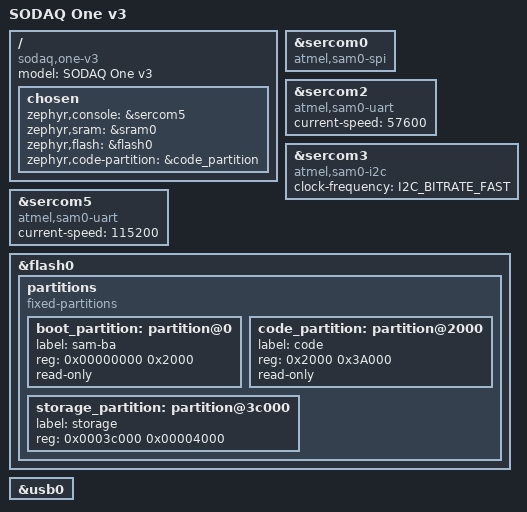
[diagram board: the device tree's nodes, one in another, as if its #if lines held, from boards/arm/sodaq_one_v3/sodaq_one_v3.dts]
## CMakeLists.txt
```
# Create following http://docs.zephyrproject.org/application/application.html

# Board used - Use custom board
#set(BOARD adafruit_feather_m0_basic_proto)
#set(BOARD_ROOT ${CMAKE_SOURCE_DIR})
set(BOARD sodaq_one_v3)

# Include zephyr
include($ENV{ZEPHYR_BASE}/cmake/app/boilerplate.cmake NO_POLICY_SCOPE)
project(NONE)

# Application source files
target_sources(app PRIVATE src/main.c)
target_sources(app PRIVATE src/RN2483_lora.c)
target_sources(app PRIVATE src/LSM303AGR.c)
target_sources(app PRIVATE src/UBloxEVA8M.c)
```

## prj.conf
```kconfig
CONFIG_SYS_LOG=y
CONFIG_SYS_LOG_DEFAULT_LEVEL=3
CONFIG_SYS_LOG_I2C_LEVEL=3
```

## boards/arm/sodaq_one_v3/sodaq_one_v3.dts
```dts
/*
 * Copyright (c) 2018 Henrik Brix Andersen <henrik@brixandersen.dk>
 *
 * SPDX-License-Identifier: Apache-2.0
 */

/dts-v1/;
#include <atmel/samd21.dtsi>

/ {
	model = "SODAQ One v3";
	compatible = "sodaq,one-v3", "atmel,samd21g18a",
			"atmel,samd21";

	chosen {
		zephyr,console = &sercom5;
		zephyr,sram = &sram0;
		zephyr,flash = &flash0;
		zephyr,code-partition = &code_partition;
	};
};

&sercom0 {
	status = "ok";
	compatible = "atmel,sam0-spi";
	#address-cells = <1>;
	#size-cells = <0>;
};

&sercom2 {
	status = "ok";
	compatible = "atmel,sam0-uart";
	current-speed = <57600>;
};

&sercom3 {
	status = "ok";
	compatible = "atmel,sam0-i2c";
	clock-frequency = <I2C_BITRATE_FAST>;
	#address-cells = <1>;
	#size-cells = <0>;
};

&sercom5 {
	status = "ok";
	compatible = "atmel,sam0-uart";
	current-speed = <115200>;
};

&flash0 {
	partitions {
		compatible = "fixed-partitions";
		#address-cells = <1>;
		#size-cells = <1>;

		boot_partition: partition@0 {
			label = "sam-ba";
			reg = <0x00000000 0x2000>;
			read-only;
		};

		code_partition: partition@2000 {
			label = "code";
			reg = <0x2000 0x3A000>;
			read-only;
		};

		/*
		 * The final 16 KiB is reserved for the application
		 * and is used by NFFS if enabled.
		 */

#if defined(CONFIG_FS_FLASH_STORAGE_PARTITION)
		storage_partition: partition@3c000 {
			label = "storage";
			reg = <0x0003c000 0x00004000>;
		};
#endif
	};
};

&usb0 {
	status = "ok";
};
```

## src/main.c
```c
/*
 * Copyright (c) 2012-2014 Wind River Systems, Inc.
 *
 * SPDX-License-Identifier: Apache-2.0
 */

#include <zephyr.h>
#include <misc/printk.h>
#include <gpio.h>
#include <board.h>
#include <device.h>
#include <uart.h>
#include <stdio.h>
#include <string.h>

#include "debug.h"
#include "RN2483_lora.h"
#include "LSM303AGR.h"
#include "UBloxEVA8M.h"

#define LORA_SPREADING_FACTOR "sf7"
#define LORA_POWER 1

#ifdef DEBUG_UBLOXEVA8M
#define DEBUG DEBUG_UBLOXEVA8M
static void print_nav_pvt_msg(char *txt, ubloxeva8m_nav_pvt_t* msg);
#endif

void gps_msg_handler(ubloxeva8m_ubx_msg* msg) {
	ubloxeva8m_nav_pvt_t pvt_msg;

	if (msg->class_id == UBLOXEVA8M_CLASS_NAV && msg->message_id == UBLOXEVA8M_MSG_NAV_PVT) {
		memcpy(&pvt_msg, msg->payload, msg->length);
		print_nav_pvt_msg("UBX-NAV-PVT: ", &pvt_msg);
	}

}

void main(void)
{
	static struct device *led0, *led1, *led2;
	int ret;
	u8_t data_buf[20] = { 0x00, 0x01, 0x02, 0x03, 0x04 };
	lsm303agr_status_t accel_status;
	int16_t accel[3];

	printk("Hello World! %s\n", CONFIG_ARCH);

	led0 = device_get_binding(LED0_GPIO_PORT);
	gpio_pin_configure(led0, LED0_GPIO_PIN, GPIO_DIR_OUT);
	led1 = device_get_binding(LED1_GPIO_PORT);
	gpio_pin_configure(led1, LED1_GPIO_PIN, GPIO_DIR_OUT);
	led2 = device_get_binding(LED2_GPIO_PORT);
	gpio_pin_configure(led2, LED2_GPIO_PIN, GPIO_DIR_OUT);

	gpio_pin_write(led0, LED0_GPIO_PIN, 1);
	gpio_pin_write(led1, LED1_GPIO_PIN, 1);
	gpio_pin_write(led2, LED2_GPIO_PIN, 1);

#if 1
	if (rn2483_lora_init(CONFIG_UART_SAM0_SERCOM2_LABEL)) {
		printk("Couldn't initialize LoRa\n");
	} else {
		printk("LoRa initialized\n");
	}

	/* Setup the RN2483 for radio */
	/* Pause mac layer */
	if (rn2483_lora_pause_mac()) {
		printk("Couldn't pause mac\n");
	}

	/* Set spreading factor */
	if (rn2483_lora_radio_set_sf(LORA_SPREADING_FACTOR)) {
		printk("Couldn't set spreading factor\n");
	}

	/* Set power output */
	if (rn2483_lora_radio_set_pwr(LORA_POWER)) {
		printk("Couldn't set radio power\n");
	}

	if (rn2483_lora_radio_tx(data_buf, 5)) {
		printk("Couldn't send data\n");
	}

	data_buf[0] = 0x05;
	data_buf[1] = 0x06;
	data_buf[2] = 0x07;
	data_buf[3] = 0x08;
	data_buf[4] = 0x09;
	if (rn2483_lora_radio_tx(data_buf, 5)) {
		printk("Couldn't send data\n");
	}
#endif

	ubloxeva8m_init(CONFIG_I2C_SAM0_SERCOM3_LABEL);
	/* Configure message handler */
	ubloxeva8m_set_callback(gps_msg_handler);
	if (ubloxeva8m_start()) {
		printk("Couldn't start UBLOXEVA8M\n");
	}
	/* Change dynamic model */
	if (ubloxeva8m_set_dynamic_model(UBLOXEVA8M_DYNMODEL_AUTOMOTIVE)) {
		printk("Couldn't set dynamic model\n");
	}

	lsm303agr_init(CONFIG_I2C_SAM0_SERCOM3_LABEL);
	printk("LSM303AGR Accelerometer Device ID: %X\n", lsm303agr_accel_get_device_id());
	printk("LSM303AGR Magnetometer Device ID: %X\n", lsm303agr_mag_get_device_id());
	if (lsm303agr_accel_enable(LSM303AGR_NORMAL_MODE, LSM303AGR_HIGH_RES_100HZ, false, (LSM303AGR_Z_AXIS | LSM303AGR_Y_AXIS | LSM303AGR_X_AXIS))) {
		printk("Couldn't enable accelerometer\n");
	}
	if (lsm303agr_accel_set_scale(LSM303AGR_8G)) {
		printk("Couldn't set accelerometer scale\n");
	}
	if (lsm303agr_get_status(&accel_status)) {
		printk("Couldn't read status");
	}
	printk("Acelerometer status: Overrun (all=%d x=%d y=%d z=%d) Data Available (all=%d x=%d y=%d =z%d)\n", accel_status.z_y_x_overrun, accel_status.x_overrun, accel_status.y_overrun, accel_status.z_overrun, accel_status.z_y_x_available, accel_status.x_available, accel_status.y_available, accel_status.z_available);
	if (lsm303agr_get_x_acceleration(&accel[0])) {
		printk("Couldn't read acceleration");
	}
	if (lsm303agr_get_y_acceleration(&accel[1])) {
		printk("Couldn't read acceleration");
	}
	if (lsm303agr_get_z_acceleration(&accel[2])) {
		printk("Couldn't read acceleration");
	}
	printk("Acceleration x=%d y=%d z=%d\n", accel[0], accel[1], accel[2]);

	while(1) {
		//printk("Hello World! %s\n", CONFIG_ARCH);
		gpio_pin_write(led2, LED2_GPIO_PIN, 1);
		gpio_pin_write(led0, LED0_GPIO_PIN, 0);
		k_sleep(200);
		gpio_pin_write(led0, LED0_GPIO_PIN, 1);
		gpio_pin_write(led1, LED1_GPIO_PIN, 0);
		k_sleep(200);
		gpio_pin_write(led1, LED1_GPIO_PIN, 1);
		gpio_pin_write(led2, LED2_GPIO_PIN, 0);
		k_sleep(200);
	}
}

#ifdef DEBUG
static void print_nav_pvt_msg(char *txt, ubloxeva8m_nav_pvt_t* msg) {
	DBG_PRINTK("UBX-NAV-PVT: %d.%d.%d %02d:%02d:%02d validity=%d fixType=%d numSV=%d lat=%d lon=%d \n", msg->day, msg->month, msg->year, msg->hour, msg->minute, msg->seconds, msg->valid, msg->fixType, msg->numSV, msg->lat, msg->lon);
}
#endif
```

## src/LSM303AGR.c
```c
/** 
 * @file LSM303AGR.c
 * @brief Module description
 *
 * Detailed module description
 *
 * @author Léonard Bise
 * @date   Jul 2, 2018
 */

#include "LSM303AGR.h"

#include "debug.h"

#define DEBUG DEBUG_LSM303AGR

#include <zephyr.h>
#include <i2c.h>

/**
 * i2c address for the LSM303AGR Accelerometer
 */
#define LSM303AGR_ACCEL_ADDR 0x19

/**
 * Device ID for the LSM303AGR Accelerometer
 */
#define LSM303AGR_ACCEL_DEVICE_ID 0x33
/**
 * i2c address for the LSM303AGR Magnetometer
 */
#define LSM303AGR_MAGN_ADDR 0x1E

/**
 * Device ID for the LSM303AGR Magnetometer
 */
#define LSM303AGR_MAGN_DEVICE_ID 0x40

/**
 * Register addresses
 */
/* Accelerometer */
#define LSM303AGR_ACCEL_WHO_AM_I_REG_ADDR 0x0F
#define LSM303AGR_ACCEL_CFG1_ADDR 0x20
#define LSM303AGR_ACCEL_CFG_ODR_POS 4
#define LSM303AGR_ACCEL_CFG_LPEN_POS 3
#define LSM303AGR_ACCEL_CFG_ZEN_POS 2
#define LSM303AGR_ACCEL_CFG_YEN_POS 1
#define LSM303AGR_ACCEL_CFG_XEN_POS 0

#define LSM303AGR_ACCEL_CFG3_ADDR 0x22

#define LSM303AGR_ACCEL_CFG4_ADDR 0x23
#define LSM303AGR_ACCEL_CFG4_HR_POS 3
#define LSM303AGR_ACCEL_CFG4_FS_POS 4

#define LSM303AGR_ACCEL_INT1_CFG_ADDR 0x30
#define LSM303AGR_ACCEL_INT1_CFG_AOI_POS 7
#define LSM303AGR_ACCEL_INT1_CFG_6D_POS 6
#define LSM303AGR_ACCEL_INT1_CFG_Z_HIGH_POS 5
#define LSM303AGR_ACCEL_INT1_CFG_Z_LOW_POS 4
#define LSM303AGR_ACCEL_INT1_CFG_Y_HIGH_POS 3
#define LSM303AGR_ACCEL_INT1_CFG_Y_LOW_POS 2
#define LSM303AGR_ACCEL_INT1_CFG_X_HIGH_POS 1
#define LSM303AGR_ACCEL_INT1_CFG_X_LOW_POS 0

#define LSM303AGR_ACCEL_STATUS_ADDR 0x27
#define LSM303AGR_ACCEL_STATUS_ZYXOR_POS 7
#define LSM303AGR_ACCEL_STATUS_ZOR_POS 6
#define LSM303AGR_ACCEL_STATUS_YOR_POS 5
#define LSM303AGR_ACCEL_STATUS_XOR_POS 4
#define LSM303AGR_ACCEL_STATUS_ZYXDA_POS 3
#define LSM303AGR_ACCEL_STATUS_ZDA_POS 2
#define LSM303AGR_ACCEL_STATUS_YDA_POS 1
#define LSM303AGR_ACCEL_STATUS_XDA_POS 0

#define LSM303AGR_ACCEL_OUT_X_L_ADDR 0x28
#define LSM303AGR_ACCEL_OUT_X_H_ADDR 0x29

#define LSM303AGR_ACCEL_OUT_Y_L_ADDR 0x2A
#define LSM303AGR_ACCEL_OUT_Y_H_ADDR 0x2B

#define LSM303AGR_ACCEL_OUT_Z_L_ADDR 0x2C
#define LSM303AGR_ACCEL_OUT_Z_H_ADDR 0x2D


/* Magnetometer */
#define LSM303AGR_MAG_WHO_AM_I_REG_ADDR 0x4F


typedef struct {
	struct device *i2c_dev;

} lsm303agr_priv_t;

static lsm303agr_priv_t lsm303agr_priv;

int lsm303agr_init(const char *device_name) {
	lsm303agr_priv.i2c_dev = device_get_binding(device_name);
	u32_t i2c_cfg = I2C_SPEED_SET(I2C_SPEED_FAST) | I2C_MODE_MASTER;

	if (!lsm303agr_priv.i2c_dev) {
		DBG_PRINTK("%s: Binding to i2c failed\n", __func__);
		return LSM303AGR_BINDING_FAILED;
	}

	if (i2c_configure(lsm303agr_priv.i2c_dev, i2c_cfg)) {
		DBG_PRINTK("%s: i2c configuration failed\n", __func__);
		return LSM303AGR_CONFIGURATION_FAILED;
	}

	/* Check device IDs */
	if (lsm303agr_accel_get_device_id() != LSM303AGR_ACCEL_DEVICE_ID ||
			lsm303agr_mag_get_device_id() != LSM303AGR_MAGN_DEVICE_ID) {
		DBG_PRINTK("%s: Unknown device IDs Accelereometer: 0x%X Magnetometer: 0x%X\n", __func__, lsm303agr_accel_get_device_id(), lsm303agr_mag_get_device_id());
		return LSM303AGR_UNKNOWN_DEVICE;
	}

	return LSM303AGR_SUCCESS;
}

uint8_t lsm303agr_accel_get_device_id() {
	uint8_t dev_id = 0xFF;
	if (lsm303agr_priv.i2c_dev) {
		if (i2c_reg_read_byte(lsm303agr_priv.i2c_dev, LSM303AGR_ACCEL_ADDR, LSM303AGR_ACCEL_WHO_AM_I_REG_ADDR, &dev_id)) {
			DBG_PRINTK("%s: Register access failed\n", __func__);
			return 0xFF;
		}
	}
	return dev_id;
}

int lsm303agr_accel_enable(lsm303agr_modes_t mode, lsm303agr_datarate_modes_t data_rate, bool low_pwr_mode, uint8_t axis_enable) {
	uint8_t reg = 0;
	if (lsm303agr_priv.i2c_dev) {
		reg = (data_rate << LSM303AGR_ACCEL_CFG_ODR_POS) | ((low_pwr_mode ? 1 : 0) << LSM303AGR_ACCEL_CFG_LPEN_POS) | axis_enable;
		if (i2c_reg_write_byte(lsm303agr_priv.i2c_dev, LSM303AGR_ACCEL_ADDR, LSM303AGR_ACCEL_CFG1_ADDR, reg)) {
			DBG_PRINTK("%s: Register access failed\n", __func__);
			return LSM303AGR_REG_ACCESS_FAILED;
		}
		/* Set operating mode */
		if (mode & 0x1) {
			reg = 1 << LSM303AGR_ACCEL_CFG4_HR_POS;
		} else {
			reg = 0;
		}
		if (i2c_reg_update_byte(lsm303agr_priv.i2c_dev, LSM303AGR_ACCEL_ADDR, LSM303AGR_ACCEL_CFG4_ADDR, (1 << LSM303AGR_ACCEL_CFG4_HR_POS), reg)) {
			DBG_PRINTK("%s: Register access failed\n", __func__);
			return LSM303AGR_REG_ACCESS_FAILED;
		}
	} else {
		DBG_PRINTK("%s: I2C bus not initialized\n", __func__);
		return LSM303AGR_NOT_INITIALIZED;
	}
	return LSM303AGR_SUCCESS;
}

int lsm303agr_accel_set_scale(lsm303agr_scales_t scale) {
	uint8_t reg = 0;
	if (lsm303agr_priv.i2c_dev) {
		reg = scale << LSM303AGR_ACCEL_CFG4_FS_POS;
		if (i2c_reg_update_byte(lsm303agr_priv.i2c_dev, LSM303AGR_ACCEL_ADDR, LSM303AGR_ACCEL_CFG4_ADDR, (1 << LSM303AGR_ACCEL_CFG4_FS_POS), reg)) {
			DBG_PRINTK("%s: Register access failed\n", __func__);
			return LSM303AGR_REG_ACCESS_FAILED;
		}
	} else {
		DBG_PRINTK("%s: I2C bus not initialized\n", __func__);
		return LSM303AGR_NOT_INITIALIZED;
	}
	return LSM303AGR_SUCCESS;
}

int lsm303agr_enable_interrupt(lsm303agr_interrupts_t interrupt) {
	uint8_t reg = 0;

	if (lsm303agr_priv.i2c_dev) {
		reg = interrupt;
		if (i2c_reg_write_byte(lsm303agr_priv.i2c_dev, LSM303AGR_ACCEL_ADDR, LSM303AGR_ACCEL_CFG3_ADDR, reg)) {
			DBG_PRINTK("%s: Register access failed\n", __func__);
			return LSM303AGR_REG_ACCESS_FAILED;
		}
	} else {
		DBG_PRINTK("%s: I2C bus not initialized\n", __func__);
		return LSM303AGR_NOT_INITIALIZED;
	}
	return LSM303AGR_SUCCESS;
}

int lsm303agr_configure_interrupt1(lsm303agr_interrupt_modes_t interrupt_mode, uint8_t interrupt_directions) {
	uint8_t reg = 0;

	if (lsm303agr_priv.i2c_dev) {
		reg = (interrupt_mode << LSM303AGR_ACCEL_INT1_CFG_6D_POS) | (interrupt_directions & 0x3F);
		if (i2c_reg_write_byte(lsm303agr_priv.i2c_dev, LSM303AGR_ACCEL_ADDR, LSM303AGR_ACCEL_INT1_CFG_ADDR, reg)) {
			DBG_PRINTK("%s: Register access failed\n", __func__);
			return LSM303AGR_REG_ACCESS_FAILED;
		}
	} else {
		DBG_PRINTK("%s: I2C bus not initialized\n", __func__);
		return LSM303AGR_NOT_INITIALIZED;
	}
	return LSM303AGR_SUCCESS;
}

int lsm303agr_get_z_acceleration(int16_t* acceleration) {
	uint8_t reg = 0;

	if (lsm303agr_priv.i2c_dev) {
		if (i2c_reg_read_byte(lsm303agr_priv.i2c_dev, LSM303AGR_ACCEL_ADDR, LSM303AGR_ACCEL_OUT_Z_H_ADDR, &reg)) {
			DBG_PRINTK("%s: Register access failed\n", __func__);
			return LSM303AGR_REG_ACCESS_FAILED;
		}
		*acceleration = reg << 8;
		if (i2c_reg_read_byte(lsm303agr_priv.i2c_dev, LSM303AGR_ACCEL_ADDR, LSM303AGR_ACCEL_OUT_Z_L_ADDR, &reg)) {
			DBG_PRINTK("%s: Register access failed\n", __func__);
			return LSM303AGR_REG_ACCESS_FAILED;
		}
		*acceleration = reg;
	} else {
		DBG_PRINTK("%s: I2C bus not initialized\n", __func__);
		return LSM303AGR_NOT_INITIALIZED;
	}
	return LSM303AGR_SUCCESS;
}

int lsm303agr_get_y_acceleration(int16_t* acceleration) {
	uint8_t reg = 0;

	if (lsm303agr_priv.i2c_dev) {
		if (i2c_reg_read_byte(lsm303agr_priv.i2c_dev, LSM303AGR_ACCEL_ADDR, LSM303AGR_ACCEL_OUT_Y_H_ADDR, &reg)) {
			DBG_PRINTK("%s: Register access failed\n", __func__);
			return LSM303AGR_REG_ACCESS_FAILED;
		}
		*acceleration = reg << 8;
		if (i2c_reg_read_byte(lsm303agr_priv.i2c_dev, LSM303AGR_ACCEL_ADDR, LSM303AGR_ACCEL_OUT_Y_L_ADDR, &reg)) {
			DBG_PRINTK("%s: Register access failed\n", __func__);
			return LSM303AGR_REG_ACCESS_FAILED;
		}
		*acceleration = reg;
	} else {
		DBG_PRINTK("%s: I2C bus not initialized\n", __func__);
		return LSM303AGR_NOT_INITIALIZED;
	}
	return LSM303AGR_SUCCESS;
}

int lsm303agr_get_x_acceleration(int16_t* acceleration) {
	uint8_t reg = 0;

	if (lsm303agr_priv.i2c_dev) {
		if (i2c_reg_read_byte(lsm303agr_priv.i2c_dev, LSM303AGR_ACCEL_ADDR, LSM303AGR_ACCEL_OUT_X_H_ADDR, &reg)) {
			DBG_PRINTK("%s: Register access failed\n", __func__);
			return LSM303AGR_REG_ACCESS_FAILED;
		}
		*acceleration = reg << 8;
		if (i2c_reg_read_byte(lsm303agr_priv.i2c_dev, LSM303AGR_ACCEL_ADDR, LSM303AGR_ACCEL_OUT_X_L_ADDR, &reg)) {
			DBG_PRINTK("%s: Register access failed\n", __func__);
			return LSM303AGR_REG_ACCESS_FAILED;
		}
		*acceleration = reg;
	} else {
		DBG_PRINTK("%s: I2C bus not initialized\n", __func__);
		return LSM303AGR_NOT_INITIALIZED;
	}
	return LSM303AGR_SUCCESS;
}

int lsm303agr_get_status(lsm303agr_status_t* status) {
	uint8_t reg = 0;

	if (lsm303agr_priv.i2c_dev) {
		if (i2c_reg_read_byte(lsm303agr_priv.i2c_dev, LSM303AGR_ACCEL_ADDR, LSM303AGR_ACCEL_STATUS_ADDR, &reg)) {
			DBG_PRINTK("%s: Register access failed\n", __func__);
			return LSM303AGR_REG_ACCESS_FAILED;
		}
		status->z_y_x_overrun = (reg & (1 << LSM303AGR_ACCEL_STATUS_ZYXOR_POS)) ? true : false;
		status->z_overrun = (reg & (1 << LSM303AGR_ACCEL_STATUS_ZOR_POS)) ? true : false;
		status->y_overrun = (reg & (1 << LSM303AGR_ACCEL_STATUS_YOR_POS)) ? true : false;
		status->x_overrun = (reg & (1 << LSM303AGR_ACCEL_STATUS_XOR_POS)) ? true : false;
		status->z_y_x_available = (reg & (1 << LSM303AGR_ACCEL_STATUS_ZYXDA_POS)) ? true : false;
		status->z_available = (reg & (1 << LSM303AGR_ACCEL_STATUS_ZDA_POS)) ? true : false;
		status->y_available = (reg & (1 << LSM303AGR_ACCEL_STATUS_YDA_POS)) ? true : false;
		status->x_available = (reg & (1 << LSM303AGR_ACCEL_STATUS_XDA_POS)) ? true : false;
	} else {
		DBG_PRINTK("%s: I2C bus not initialized\n", __func__);
		return LSM303AGR_NOT_INITIALIZED;
	}
	return LSM303AGR_SUCCESS;
}

uint8_t lsm303agr_mag_get_device_id() {
	uint8_t dev_id = 0xFF;
	if (lsm303agr_priv.i2c_dev) {
		if (i2c_reg_read_byte(lsm303agr_priv.i2c_dev, LSM303AGR_MAGN_ADDR, LSM303AGR_MAG_WHO_AM_I_REG_ADDR, &dev_id)) {
			DBG_PRINTK("%s: Register access failed\n", __func__);
			return 0xFF;
		}
	}
	return dev_id;
}
```

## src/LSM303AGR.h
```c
/** 
 * @file LSM303AGR.h
 * @brief Module description
 *
 * Detailed module description
 *
 * @author Léonard Bise
 * @date   Jul 2, 2018
 */
#ifndef SRC_LSM303AGR_H_
#define SRC_LSM303AGR_H_

#include <stdint.h>
#include <stdbool.h>

/**
 * Return types of the LSM303AGR functions
 */
#define LSM303AGR_SUCCESS 0
#define LSM303AGR_BINDING_FAILED -1
#define LSM303AGR_CONFIGURATION_FAILED -2
#define LSM303AGR_NOT_INITIALIZED -3
#define LSM303AGR_REG_ACCESS_FAILED -4
#define LSM303AGR_UNKNOWN_DEVICE -5

/**
 * Module status
 */
typedef struct {
	bool z_y_x_overrun;
	bool z_overrun;
	bool y_overrun;
	bool x_overrun;
	bool z_y_x_available;
	bool z_available;
	bool y_available;
	bool x_available;
} lsm303agr_status_t;

/**
 * Device mode
 */
typedef enum {
	LSM303AGR_NORMAL_MODE,
	LSM303AGR_HIGH_RES_MODE,
	LSM303AGR_LOW_PWR_MODE
} lsm303agr_modes_t;

/**
 * Data rate and operating modes of the accelerometer
 */
typedef enum {
	LSM303AGR_PWR_DOWN_MODE,
	LSM303AGR_HIGH_RES_1HZ,
	LSM303AGR_HIGH_RES_10HZ,
	LSM303AGR_HIGH_RES_25HZ,
	LSM303AGR_HIGH_RES_50HZ,
	LSM303AGR_HIGH_RES_100HZ,
	LSM303AGR_HIGH_RES_200HZ,
	LSM303AGR_HIGH_RES_400HZ,
	LSM303AGR_LOW_PWR_MODE_1620HZ,
	LSM303AGR_HIGH_RES_5376HZ
} lsm303agr_datarate_modes_t;

/* Accelerometer axes */
#define LSM303AGR_Z_AXIS (1 << 2)
#define LSM303AGR_Y_AXIS (1 << 1)
#define LSM303AGR_X_AXIS (1 << 0)

typedef enum {
	LSM303AGR_2G,
	LSM303AGR_4G,
	LSM303AGR_8G,
	LSM303AGR_16G
} lsm303agr_scales_t;

typedef enum {
	LSM303AGR_INT_OR_COMBINATION,
	LSM303AGR_INT_MOVEMENT_RECOG,
	LSM303AGR_INT_AND_COMBINATION,
	LSM303AGR_INT_POSITION_RECOG
} lsm303agr_interrupt_modes_t;

typedef enum {
	LSM303AGR_INT_DIR_Z_HIGH = 32,
	LSM303AGR_INT_DIR_Z_LOW = 16,
	LSM303AGR_INT_DIR_Y_HIGH = 8,
	LSM303AGR_INT_DIR_Y_LOW = 4,
	LSM303AGR_INT_DIR_X_HIGH = 2,
	LSM303AGR_INT_DIR_X_LOW = 1,
} lsm303agr_interrupt_directions_t;

typedef enum {
	LSM303AGR_INT_CLICK,
	LSM303AGR_INT_AOI1,
	LSM303AGR_INT_AOI2,
	LSM303AGR_INT_DRDY1,
	LSM303AGR_INT_DRDY2,
	LSM303AGR_INT_WTM,
	LSM303AGR_INT_OVERRUN
} lsm303agr_interrupts_t;

/**
 * Initialize the LSM303AGR Magnetometer and accelerometer module
 * @param device_name I2C device name
 * @return
 */
int lsm303agr_init(const char *device_name);

/**
 * Returns the accelerometer device ID
 * @return
 */
uint8_t lsm303agr_accel_get_device_id();

/**
 * Enable the LSM303AGR Accelerometer
 */
int lsm303agr_accel_enable(lsm303agr_modes_t mode, lsm303agr_datarate_modes_t data_rate, bool low_pwr_mode, uint8_t axis_enable);

/**
 * Sets the accelerometer scale
 * @param scale
 * @return
 */
int lsm303agr_accel_set_scale(lsm303agr_scales_t scale);

/**
 * Configure interrupt 1 generation
 * @param interrupt_mode
 * @param interrupt_directions
 * @return
 */
int lsm303agr_configure_interrupt1(lsm303agr_interrupt_modes_t interrupt_mode, uint8_t interrupt_directions);

/**
 * Enable the interrupt generation
 * @param interrupt
 * @return
 */
int lsm303agr_enable_interrupt(lsm303agr_interrupts_t interrupt);

/**
 * Returns the Z axis acceleration
 * @param acceleration
 * @return
 */
int lsm303agr_get_z_acceleration(int16_t* acceleration);

/**
 * Returns the Y axis acceleration
 * @param acceleration
 * @return
 */
int lsm303agr_get_y_acceleration(int16_t* acceleration);

/**
 * Returns the X axis acceleration
 * @param acceleration
 * @return
 */
int lsm303agr_get_x_acceleration(int16_t* acceleration);

/**
 * Returns the status of the accelerometer
 * @param status
 * @return
 */
int lsm303agr_get_status(lsm303agr_status_t* status);

/**
 * Returns the magnetometerdevice ID
 * @return
 */
uint8_t lsm303agr_mag_get_device_id();

#endif /* SRC_LSM303AGR_H_ */
```

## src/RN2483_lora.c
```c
/** 
 * @file RN2483_lora.c
 * @brief Module description
 *
 * Detailed module description
 *
 * @author Léonard Bise
 * @date   Jun 28, 2018
 */

#include "RN2483_lora.h"

#include "debug.h"

#include <string.h>
#include <stdio.h>

#include <device.h>
#include <board.h>
#include <gpio.h>
#include <uart.h>
#include <misc/printk.h>
#include <kernel.h>

/**
 * Pin used for the reset of the module
 */
#define RN2483_LORA_RESET_PORT LORA_RESET_GPIO_PORT
#define RN2483_LORA_RESET_PIN LORA_RESET_GPIO_PIN

/**
 * Command to transmit radio
 */
#define RN2483_LORA_RADIO_TX_CMD "radio tx "
/**
 * Size of the command to transmit radio (nb chars)
 */
#define RN2483_LORA_RADIO_TX_CMD_SIZE 9

/**
 * Maximum payload size
 */
#define RN2483_LORA_MAX_PAYLOAD_SIZE 222

/**
 * LoRa UART device
 */
static struct device *lora_uart;

/**
 * Thread stack size
 */
#define RN2483_LORA_STACKSIZE 1024

/**
 * Thread priority
 */
#define RN2483_LORA_PRIORITY 7

/**
 * Amount of time the thread sleeps after each iterations
 */
#define RN2483_LORA_THREAD_SLEEP_MS 100

/**
 *  Buffer size
 */
#define BUFF_SIZE 256

/**
 * RX Data Buffer
 */
u32_t rx_data_buf_idx = 0;
u8_t rx_data_buf[BUFF_SIZE];

/**
 * RX data is ready
 */
static volatile bool rx_data_rdy = false;

/**
 * Ready to send (i.e. received system ver at beginning)
 */
static volatile bool ready_to_send = false;

/**
 * New command is ready to be sent
 */
static volatile bool new_cmd_rdy = false;

/**
 * Command index and buffer
 */
u32_t cmd_idx = 0;
u8_t cmd_buf[BUFF_SIZE];

/**
 * Wait for buffer
 */
static volatile bool wait_for = false;
char wait_for_buf[BUFF_SIZE];

static void rn2483_lora_irq_handler(struct device *dev) {
	int bytes_read;

	uart_irq_update(dev);

	/* TODO IRQ on TX seem to spin forever */
	/*if (uart_irq_tx_ready(dev)) {
	}*/

	if (uart_irq_rx_ready(dev)) {
		/* Data is available for reading */
		while ((bytes_read = uart_fifo_read(dev, (u8_t *)(&rx_data_buf[rx_data_buf_idx]), sizeof(rx_data_buf) - rx_data_buf_idx))) {
			/* Check last char */
			if (rx_data_buf[rx_data_buf_idx + bytes_read - 1] == '\n') {
				rx_data_rdy = true;
				/* Discard carriage return */
				rx_data_buf[rx_data_buf_idx + bytes_read - 1] = '\0';
			}
			rx_data_buf_idx += bytes_read;
		}
	}
}

void rn2483_lora_thread(void) {
	char sent;

	printk("%s\n", __func__);

	while(1) {
		if (rx_data_rdy) {
			if (!ready_to_send) {
				/* Before being able to send anything, we need
				 * to wait for the sys version from the RN2483 */
				ready_to_send = true;
			}

			if (wait_for) {
				if (wait_for_buf[0] == '\0') {
					/* Wait for any reply */
					wait_for = false;
				} else {
					/* Check the reply */
					if (strcmp(wait_for_buf, rx_data_buf) == 0) {
						wait_for = false;
					}
				}
			}
			/* setup for new reading */
			rx_data_rdy = false;
			rx_data_buf_idx = 0;

			DBG_PRINTK("%s: RX: %s\n", __func__, rx_data_buf);
		}

		if (ready_to_send && new_cmd_rdy) {
			/* Send command by polling */
			sent = uart_poll_out(lora_uart, cmd_buf[cmd_idx]);
			if (sent == '\n') {
				new_cmd_rdy = false;
				DBG_PRINTK("%s: TX: %s\n", __func__, cmd_buf);
			}
			cmd_idx++;
		}
		/* TODO uart_err_check */
		k_sleep(RN2483_LORA_THREAD_SLEEP_MS);
	}
}

int rn2483_lora_cmd(char* cmd) {
	if (!new_cmd_rdy) {
		if (strlen(cmd) <= (BUFF_SIZE - 2)) {
			memcpy(cmd_buf, cmd, strlen(cmd));
			cmd_buf[strlen(cmd)] = '\r';
			cmd_buf[strlen(cmd) + 1] = '\n';
			new_cmd_rdy = true;
			cmd_idx = 0;
		} else {
			DBG_PRINTK("%s: Cmd too long %d (max:%d)\n", __func__, strlen(cmd), BUFF_SIZE);
			return RN2483_LORA_CMD_TOO_LONG;
		}
	} else {
		DBG_PRINTK("%s: Module busy\n", __func__);
		return RN2483_LORA_BUSY;
	}
	return RN2483_LORA_SUCCESS;
}

void rn2483_lora_wait_for_any_reply() {
	if (!wait_for) {
		wait_for_buf[0] = '\0';
		wait_for = true;
		while(wait_for) {
			k_sleep(200);
		}
	}
}

void rn2483_lora_wait_for_reply(char* reply) {
	if (!wait_for && strlen(reply) <= (BUFF_SIZE - 2)) {
		strcpy(wait_for_buf, reply);
		wait_for_buf[strlen(wait_for_buf)] = '\r';
		wait_for_buf[strlen(wait_for_buf)+1] = '\0';
		wait_for = true;
		while(wait_for) {
			k_sleep(200);
		}
	}
}

void rn2483_lora_wait_cmd() {
	while(new_cmd_rdy) {
		k_sleep(200);
	}
}

int rn2483_lora_init(const char *device_name) {
	rx_data_rdy = false;
	rx_data_buf_idx = 0;
	new_cmd_rdy = false;
	ready_to_send = false;

	/* Reset device */
	if (rn2483_lora_reset()) {
		return RN2483_LORA_BINDING_FAILED;
	}
	/* Bind to LoRa UART */
	lora_uart = device_get_binding(device_name);
	if (!lora_uart) {
		DBG_PRINTK("%s: Couldn't bind LoRa UART device\n", __func__);
		return RN2483_LORA_BINDING_FAILED;
	}
	/* Configure interrupt handler */
	uart_irq_callback_set(lora_uart, rn2483_lora_irq_handler);

	/* Enable interrupts */
	uart_irq_rx_enable(lora_uart);

	/* Wait for the reading of the system version */
	while(!ready_to_send) {
		k_sleep(200);
	}

	return RN2483_LORA_SUCCESS;
}

int rn2483_lora_reset() {
	static struct device *lora_reset;
	/* Reset LoRa module */
	lora_reset = device_get_binding(RN2483_LORA_RESET_PORT);
	if (!lora_reset) {
		DBG_PRINTK("%s: Couldn't bind LoRa Reset device\n", __func__);
		return RN2483_LORA_BINDING_FAILED;
	}
	/* Set pin direction */
	gpio_pin_configure(lora_reset, RN2483_LORA_RESET_PIN, GPIO_DIR_OUT);

	/* Set pin low */
	gpio_pin_write(lora_reset, RN2483_LORA_RESET_PIN, 0);
	/* Wait 100ms */
	k_busy_wait(100000);
	/* Set pin high */
	gpio_pin_write(lora_reset, RN2483_LORA_RESET_PIN, 1);
	/* Wait 100ms */
	k_busy_wait(100000);

	return RN2483_LORA_SUCCESS;
}

int rn2483_lora_radio_tx(u8_t* data, u32_t size) {
	char cmd_buf[BUFF_SIZE];
	char tmp[3];
	int i;

	if (!new_cmd_rdy) {
		if (size <= RN2483_LORA_MAX_PAYLOAD_SIZE) {
			strcpy(cmd_buf, RN2483_LORA_RADIO_TX_CMD);
			for(i = 0; i < size; i++) {
				snprintf(tmp, 3, "%02X", data[i]);
				strcat(cmd_buf, tmp);
			}
			/* Send command */
			return rn2483_lora_cmd(cmd_buf);
		} else {
			DBG_PRINTK("%s: Command too long %d (max %d)\n", __func__, size, RN2483_LORA_MAX_PAYLOAD_SIZE);
			return RN2483_LORA_CMD_TOO_LONG;
		}
	} else {
		DBG_PRINTK("%s: Module busy\n", __func__);
		return RN2483_LORA_BUSY;
	}
	return RN2483_LORA_SUCCESS;
}

/* Thread definition for the RN2483 LoRa module */
K_THREAD_DEFINE(rn2483_lora_thread_id, RN2483_LORA_STACKSIZE, rn2483_lora_thread, NULL, NULL, NULL, RN2483_LORA_PRIORITY, 0, K_NO_WAIT);
```

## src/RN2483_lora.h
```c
/** 
 * @file RN2483_lora.h
 * @brief Module description
 *
 * Detailed module description
 *
 * @author Léonard Bise
 * @date   Jun 28, 2018
 */
#ifndef SRC_RN2483_LORA_H_
#define SRC_RN2483_LORA_H_

#include <zephyr.h>

/* Error Statuses returned by the RN2483 LoRa module */
#define RN2483_LORA_SUCCESS 0
#define RN2483_LORA_BINDING_FAILED -1
#define RN2483_LORA_BUSY -2
#define RN2483_LORA_CMD_TOO_LONG -3
#define RN2483_LORA_TOO_MANY_REPLIES -4
#define RN2483_LORA_ERR_REPLY -6

/**
 * Initialze the RN2483 LoRa module
 * @param device_name UART device name
 * @return
 */
int rn2483_lora_init(const char *device_name);

/**
 * Reset the RN2483 Lora module
 * @return
 */
int rn2483_lora_reset();

/**
 * Pause the MAC layer
 * \note Use when you only want LoRa radio
 * @return
 */
int rn2483_lora_pause_mac();

/**
 * Sets the spreading factor of the LoRa radio
 * @param sf Spreading factor (sf7 .. sf12)
 * @return
 */
int rn2483_lora_radio_set_sf(char* sf);

/**
 * Sets the power of the LoRa radio output
 * @param pwr
 * @return
 */
int rn2483_lora_radio_set_pwr(u8_t pwr);

/**
 * Send data through LoRa radio
 * @return
 */
int rn2483_lora_radio_tx(u8_t* data, u32_t size);

#endif /* SRC_RN2483_LORA_H_ */
```

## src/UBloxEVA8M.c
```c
/** 
 * @file UBloxEVA8M.c
 * @brief Module description
 *
 * Detailed module description
 *
 * @author Léonard Bise
 * @date   Jul 9, 2018
 */

#include "UBloxEVA8M.h"

#include "debug.h"

#define DEBUG DEBUG_UBLOXEVA8M

#include "UBloxEVA8M_protocol.h"

#include <i2c.h>
#include <board.h>
#include <gpio.h>
#include <string.h>

#ifdef DEBUG
#include <stdio.h>
#endif

/**
 * Thread stack size
 */
#define UBLOXEVA8M_STACKSIZE 1024

/**
 * Thread priority
 */
#define UBLOXEVA8M_PRIORITY 7

/**
 * Amount of milliseconds the thread sleeps after each iteration
 */
#define UBLOXEVA8M_THREAD_SLEEP_MS 100

/**
 * I2C Device Address
 */
#define UBLOXEVA8M_ADDR 0x42

/**
 * I2C Register Addresses
 */
/* 16 bits number of bytes in the message stream */
#define UBLOXEVA8M_NB_BYTES_STREAM_ADDR 0xFD
/* Address where the stream can be read from */
#define UBLOXEVA8M_STREAM_ADDR 0xFF

/* Sync char 1 character */
#define UBLOXEVA8M_SYNCH_CHAR_1 0xB5
/* Sync char 2 character */
#define UBLOXEVA8M_SYNCH_CHAR_2 0x62

/**
 * Number of iterations before declaring the module is dead
 */
#define UBLOXEVA8M_IS_ALIVE_TIMEOUT_ITER 50

/**
 * Structure used internally
 */
typedef struct {
	struct device *i2c_dev;
	struct device *gps_enable;
	struct device *gps_timepulse;
	bool is_thread_running;
} ubloxeva8m_priv_t;

/**
 * Internal structure
 */
static ubloxeva8m_priv_t ubloxeva8m_priv;

/**
 * States used during message processing
 */
#define UBLOXEVA8M_STATE_SYNCH_CHAR_1 0
#define UBLOXEVA8M_STATE_SYNCH_CHAR_2 1
#define UBLOXEVA8M_STATE_CLASS 2
#define UBLOXEVA8M_STATE_MSG_ID 3
#define UBLOXEVA8M_STATE_LEN_1 4
#define UBLOXEVA8M_STATE_LEN_2 5
#define UBLOXEVA8M_STATE_PAYLOAD 6
#define UBLOXEVA8M_STATE_CSUM_A 7
#define UBLOXEVA8M_STATE_CSUM_B 8

/**
 * Size of a message
 */
#define UBLOXEVA8M_MSG_BUFFER_SIZE (4 + UBLOXEVA8M_MSG_PAYLOAD_BUFFER_SIZE + 2)

/**
 * Size of the SYNCH chars
 */
#define UBLOXEVA8M_SYNC_CHAR_SIZE 1

/**
 * Size of the class ID
 */
#define UBLOXEVA8M_CLASS_ID_SIZE 1

/**
 * Size of the message ID
 */
#define UBLOXEVA8M_MSG_ID_SIZE 1

/**
 * Size of the length
 */
#define UBLOXEVA8M_LENGTH_SIZE 2

/**
 * Size of the checksum
 */
#define UBLOXEVA8M_CSUM_SIZE 2

/**
 * The size of a message with no payload
 */
#define UBLOXEVA8M_MSG_PARAM_SIZE (2 * UBLOXEVA8M_SYNC_CHAR_SIZE + UBLOXEVA8M_CLASS_ID_SIZE + UBLOXEVA8M_MSG_ID_SIZE + UBLOXEVA8M_LENGTH_SIZE + UBLOXEVA8M_CSUM_SIZE)

/**
 * Current state of process data
 */
static uint8_t current_state = 0;

/**
 * Current UBX message being processed
 */
static ubloxeva8m_ubx_msg current_msg;

/**
 * Callback function
 */
static ubloxeva8m_msg_callback msg_handler = NULL;

/* Forward declarations */
#ifdef DEBUG_MSG
static void print_msg(char* txt, ubloxeva8m_ubx_msg* msg);
#endif

#define UBLOXEVA8M_NB_CLASS_IDS 4
#define UBLOXEVA8M_NB_MSG_IDS 4

typedef struct {
	uint8_t class_ids[UBLOXEVA8M_NB_CLASS_IDS];
	uint8_t message_ids[UBLOXEVA8M_NB_MSG_IDS];
	int nb;
	ubloxeva8m_ubx_msg* msg_recv;
} ubloxeva8m_wait_for_t;

static ubloxeva8m_wait_for_t wait_for;

/**
 * Define semaphore used for wait for mechanism
 */
K_SEM_DEFINE(sem_wait_for, 0, 1);

typedef struct {
	uint8_t msg[UBLOXEVA8M_MSG_BUFFER_SIZE];
	int length;
} ubloxeva8m_send_msg_t;

static ubloxeva8m_send_msg_t msg_to_send;

/* The thread id for UBloxEVA8M */
extern const k_tid_t ubloxeva8m_thread_id;

static uint16_t calc_csum(uint8_t* data, uint16_t length) {
	uint8_t csum_a = 0, csum_b = 0;
	for(int i = 0; i < length; i++) {
		csum_a = csum_a + data[i];
		csum_b = csum_b + csum_a;
	}
	return (uint16_t)(csum_a << 8 | (csum_b & 0xFF));
}

static uint16_t get_nb_available_data() {
	uint8_t tmp;
	uint16_t reg;

	if (!ubloxeva8m_priv.i2c_dev) {
		DBG_PRINTK("%s: Module not initialized\n", __func__);
		return 0;
	}
	if (i2c_reg_read_byte(ubloxeva8m_priv.i2c_dev, UBLOXEVA8M_ADDR, UBLOXEVA8M_NB_BYTES_STREAM_ADDR, &tmp)) {
		DBG_PRINTK("%s: Register #1 access failed\n", __func__);
		return 0;
	}
	reg = tmp << 8;
	if (i2c_reg_read_byte(ubloxeva8m_priv.i2c_dev, UBLOXEVA8M_ADDR, UBLOXEVA8M_NB_BYTES_STREAM_ADDR + 1, &tmp)) {
		DBG_PRINTK("%s: Register #2 access failed\n", __func__);
		return 0;
	}
	reg |= tmp;
	return reg;
}

static uint8_t read_stream_byte() {
	uint8_t data;

	if (i2c_reg_read_byte(ubloxeva8m_priv.i2c_dev, UBLOXEVA8M_ADDR, UBLOXEVA8M_STREAM_ADDR, &data)) {
		DBG_PRINTK("%s: Register access failed\n", __func__);
	}
	return data;
}

/**
 * Reset a message
 * @param msg Message to reset
 */
static void reset_msg(ubloxeva8m_ubx_msg* msg) {
	msg->class_id = 0xFF;
	msg->message_id = 0xFF;
	msg->length = 0;
	msg->stored_length = 0;
	msg->checksum = 0;
}

/**
 * Process a new byte of data
 * The data received uses the UBX protocol as defined in document
 * u-blox8-M8_ReceiverDescrProtSpec_(UBX-13003221)_Public.pdf
 *
 * The format of an UBX message is described here:
 * 	- Synch Char #1 : 1 byte : 0xB5
 * 	- Synch Char #2 : 1 byte : 0x62
 * 	- Class 		: 1 byte : Message Class
 * 	- ID 			: 1 byte : Message ID
 * 	- Length		: 2 byte : UBX Message payload length (little endian)
 * 	- Payload		: X byte : UBX Message payload
 * 	- Checksum A	: 1 byte : Checksum part A
 * 	- Checksum B	: 1 byte : Checksum part B
 *
 * 	The 16bit checksum is calculated over the Class, ID, Length and Payload fields.
 *
 * @param data
 * @return true = msg ready, false = msg incomplete
 */
static bool process_data(uint8_t data) {
	bool ret = false;
	switch(current_state) {
	case UBLOXEVA8M_STATE_SYNCH_CHAR_1:
		if (data == UBLOXEVA8M_SYNCH_CHAR_1) {
			current_state = UBLOXEVA8M_STATE_SYNCH_CHAR_2;
			reset_msg(&current_msg);
		}
		break;
	case UBLOXEVA8M_STATE_SYNCH_CHAR_2:
		if (data == UBLOXEVA8M_SYNCH_CHAR_2) {
			current_state = UBLOXEVA8M_STATE_CLASS;
		}
		break;
	case UBLOXEVA8M_STATE_CLASS:
		current_msg.class_id = data;
		current_state = UBLOXEVA8M_STATE_MSG_ID;
		break;
	case UBLOXEVA8M_STATE_MSG_ID:
		current_msg.message_id = data;
		current_state = UBLOXEVA8M_STATE_LEN_1;
		break;
	case UBLOXEVA8M_STATE_LEN_1:
		current_msg.length = data & 0xFF;
		current_state = UBLOXEVA8M_STATE_LEN_2;
		break;
	case UBLOXEVA8M_STATE_LEN_2:
		current_msg.length |= (data << 8);
		current_state = UBLOXEVA8M_STATE_PAYLOAD;
		if (current_msg.length > UBLOXEVA8M_MSG_PAYLOAD_BUFFER_SIZE) {
			DBG_PRINTK("%s: Payload length %d larger than buffer. Resetting to inital state\n", __func__, current_msg.length);
			current_state = UBLOXEVA8M_STATE_SYNCH_CHAR_1;
		}
		break;
	case UBLOXEVA8M_STATE_PAYLOAD:
		current_msg.payload[current_msg.stored_length] = data;
		current_msg.stored_length++;
		if (current_msg.length == current_msg.stored_length) {
			current_state = UBLOXEVA8M_STATE_CSUM_A;
		}
		break;
	case UBLOXEVA8M_STATE_CSUM_A:
		current_msg.checksum = data << 8;
		current_state = UBLOXEVA8M_STATE_CSUM_B;
		break;
	case UBLOXEVA8M_STATE_CSUM_B:
		current_msg.checksum |= data;
		current_state = UBLOXEVA8M_STATE_SYNCH_CHAR_1;
		ret = true;
		break;
	default:
		DBG_PRINTK("%s: Unknown State. Resetting to inital state\n", __func__);
		current_state = UBLOXEVA8M_STATE_SYNCH_CHAR_1;
		break;
	}
	return ret;
}

static void process_msg(ubloxeva8m_ubx_msg* msg) {
	for(int i = 0; i < wait_for.nb; i++) {
		if (wait_for.class_ids[i] == msg->class_id && wait_for.message_ids[i] == msg->message_id) {
			if (wait_for.msg_recv != NULL) {
				memcpy(wait_for.msg_recv, msg, sizeof(msg));
			}
			wait_for.nb = 0;
			k_sem_give(&sem_wait_for);
			break;
		}
	}
	if (msg_handler) {
		msg_handler(msg);
	}
}

static bool wait_for_messages(uint8_t* class_id, uint8_t* message_id, int nb, ubloxeva8m_ubx_msg* msg_recv) {
	if (wait_for.nb > 0) {
		DBG_PRINTK("%s: Already waiting!\n", __func__);
		return false;
	}
	wait_for.nb = nb;
	wait_for.msg_recv = msg_recv;
	for(int i = 0; i < wait_for.nb; i++) {
		wait_for.class_ids[i] = class_id[i];
		wait_for.message_ids[i] = message_id[i];
	}
	/* Wait for message */
	k_sem_take(&sem_wait_for, K_FOREVER);
	return true;
}

static bool wait_for_message(uint8_t class_id, uint8_t message_id, ubloxeva8m_ubx_msg* msg_recv) {
	return wait_for_messages(&class_id, &message_id, 1, msg_recv);
}

/**
 * Wait for ACK or NAK
 * @return true = ACK, false = NAK
 */
static bool wait_for_ack() {
	uint8_t class_ids[2] = { UBLOXEVA8M_CLASS_ACK, UBLOXEVA8M_CLASS_ACK };
	uint8_t message_ids[2] = { UBLOXEVA8M_MSG_ACK_ACK, UBLOXEVA8M_MSG_ACK_NAK };
	ubloxeva8m_ubx_msg msg_recv;

	if (wait_for_messages(class_ids, message_ids, 2, &msg_recv)) {
		if (msg_recv.class_id == UBLOXEVA8M_CLASS_ACK && msg_recv.message_id == UBLOXEVA8M_MSG_ACK_ACK) {
			return true;
		}
		if (msg_recv.class_id == UBLOXEVA8M_CLASS_ACK && msg_recv.message_id == UBLOXEVA8M_MSG_ACK_NAK) {
			return false;
		}
	}
	return false;
}

static int send_msg(uint8_t class_id, uint8_t message_id, uint8_t* payload, uint16_t length) {
	uint16_t csum;

	if (msg_to_send.length > 0) {
		DBG_PRINTK("%s: I2C Busy\n", __func__);
		return UBLOXEVA8M_BUSY;
	}
	/* Create message */
	msg_to_send.msg[0] = UBLOXEVA8M_SYNCH_CHAR_1;
	msg_to_send.msg[1] = UBLOXEVA8M_SYNCH_CHAR_2;
	msg_to_send.msg[2] = class_id;
	msg_to_send.msg[3] = message_id;
	/* Little endian */
	/* 0x0102 */
	msg_to_send.msg[4] = length & 0xFF;
	msg_to_send.msg[5] = length >> 8;
	/* Copy payload */
	memcpy(&msg_to_send.msg[6], payload, length);
	csum = calc_csum(&msg_to_send.msg[2], length + 4);
	msg_to_send.msg[6 + length] = csum >> 8;
	msg_to_send.msg[6 + 1 + length] = csum & 0xFF;
#ifdef DEBUG
	DBG_PRINTK("%s: Sending: ", __func__);
	for(int i = 0; i < (length + UBLOXEVA8M_MSG_PARAM_SIZE); i++) {
		DBG_PRINTK("%02X", msg_to_send.msg[i]);
	}
	DBG_PRINTK("\n");
#endif
	msg_to_send.length = length + UBLOXEVA8M_MSG_PARAM_SIZE;
	return UBLOXEVA8M_SUCCESS;
}

static int get_protocol_configuration(ubloxeva8m_cfg_prt_t* msg) {
	int status;

	if (msg == NULL) {
		DBG_PRINTK("%s: NULL pointer\n", __func__);
		return UBLOXEVA8M_NULL_POINTER;
	}

	/* Request protocol configuration from device */
	status = send_msg(UBLOXEVA8M_CLASS_CFG, UBLOXEVA8M_MSG_CFG_PRT, NULL, 0);
	if (status) {
		return status;
	}

	/* Wait for device answer containing the payload */
	wait_for_message(UBLOXEVA8M_CLASS_CFG, UBLOXEVA8M_MSG_CFG_PRT, NULL);

	/* Wait for Acknowledgment */
	if (!wait_for_ack()) {
		DBG_PRINTK("%s: Module returned NACK\n", __func__);
		return UBLOXEVA8M_NACK;
	}

	/* Copy message */
	memcpy(msg, &current_msg.payload, current_msg.length);

	return UBLOXEVA8M_SUCCESS;
}

static void flush_stream() {
	uint16_t nb_byte;
	uint8_t data;
	nb_byte = get_nb_available_data();
	for(int i = 0; i < nb_byte; i++) {
		data = read_stream_byte();
	}
}

static int configure_protocol() {
	int status;
	ubloxeva8m_cfg_prt_t msg;

	/* Read current configuration from device */
	status = get_protocol_configuration(&msg);
	if (status) {
		return status;
	}

	/* Enable only UBX as output protocol */
	msg.outProtoMask = UBLOXEVA8M_CFG_PRT_OUTPROTOMASK_UBX_MASK;

	/* Send back message to update the configuration */
	status = send_msg(UBLOXEVA8M_CLASS_CFG, UBLOXEVA8M_MSG_CFG_PRT, (uint8_t*)&msg, sizeof(msg));
	if (status) {
		return status;
	}

	/* Wait for Acknowledgment */
	if (!wait_for_ack()) {
		DBG_PRINTK("%s: Module returned NACK\n", __func__);
		return UBLOXEVA8M_NACK;
	}

	return UBLOXEVA8M_SUCCESS;
}

static int configure_msg_rates(uint8_t class_id, uint8_t message_id, uint8_t rate) {
	int status;
	ubloxeva8m_cfg_msg_t msg;

	msg.msgClass = class_id;
	msg.msgID = message_id;
	msg.rate = rate;

	status = send_msg(UBLOXEVA8M_CLASS_CFG, UBLOXEVA8M_MSG_CFG_MSG, (uint8_t*)&msg, sizeof(msg));
	if (status) {
		return status;
	}

	/* Wait for Acknowledgment */
	if (!wait_for_ack()) {
		DBG_PRINTK("%s: Module returned NACK\n", __func__);
		return UBLOXEVA8M_NACK;
	}

	return UBLOXEVA8M_SUCCESS;
}

void ubloxeva8m_thread(void) {
	uint16_t nb_byte;
	uint8_t data;

	DBG_PRINTK("%s: Enter thread\n", __func__);

	while(1) {
		if (ubloxeva8m_priv.is_thread_running) {
			nb_byte = get_nb_available_data();
			if (nb_byte > 0) {
				for(int i = 0; i < nb_byte; i++) {
					/* Read a byte from the device stream */
					data = read_stream_byte();
					if (process_data(data)) {
						/* Message complete */
						process_msg(&current_msg);
					}
				}
			}
			/* Check if new command to send */
			if (msg_to_send.length > 0) {
				/* Send message over i2c */
				if (i2c_write(ubloxeva8m_priv.i2c_dev, msg_to_send.msg, msg_to_send.length, UBLOXEVA8M_ADDR)) {
					DBG_PRINTK("%s: I2C access failed\n", __func__);
				}
				msg_to_send.length = 0;
			}
		}
		k_sleep(UBLOXEVA8M_THREAD_SLEEP_MS);
	}
}

bool ubloxeva8m_is_alive() {
	u8_t val;
	uint32_t cnt = 0;
	while(cnt < UBLOXEVA8M_IS_ALIVE_TIMEOUT_ITER && i2c_reg_read_byte(ubloxeva8m_priv.i2c_dev, UBLOXEVA8M_ADDR, UBLOXEVA8M_NB_BYTES_STREAM_ADDR, &val)) {
		cnt++;
	}
	return cnt == UBLOXEVA8M_IS_ALIVE_TIMEOUT_ITER ? false : true;
}

int ubloxeva8m_init(const char *device_name) {
	ubloxeva8m_priv.i2c_dev = device_get_binding(device_name);
	u32_t i2c_cfg = I2C_SPEED_SET(I2C_SPEED_FAST) | I2C_MODE_MASTER;

	DBG_PRINTK("%s: Thread id %p\n", __func__, ubloxeva8m_thread_id);

	current_state = 0;
	ubloxeva8m_priv.is_thread_running = false;
	wait_for.nb = 0;

	/* Configure I2C Device */
	if (!ubloxeva8m_priv.i2c_dev) {
		DBG_PRINTK("%s: Binding to i2c failed\n", __func__);
		return UBLOXEVA8M_BINDING_FAILED;
	}
	if (i2c_configure(ubloxeva8m_priv.i2c_dev, i2c_cfg)) {
		DBG_PRINTK("%s: i2c configuration failed\n", __func__);
		return UBLOXEVA8M_CONFIGURATION_FAILED;
	}

	/* Configure GPIO GPS Enable Device */
	ubloxeva8m_priv.gps_enable = device_get_binding(GPS_EN_GPIO_PORT);
	if (!ubloxeva8m_priv.gps_enable) {
		DBG_PRINTK("%s: Binding to gpio failed\n", __func__);
		return UBLOXEVA8M_BINDING_FAILED;
	}
	if (gpio_pin_configure(ubloxeva8m_priv.gps_enable, GPS_EN_GPIO_PIN, GPIO_DIR_OUT)) {
		DBG_PRINTK("%s: Couldn't configure gpio\n", __func__);
		return UBLOXEVA8M_GPIO_ACCESS_FAILED;
	}

	/* Configure GPIO Timepulse Device */
	ubloxeva8m_priv.gps_timepulse = device_get_binding(GPS_TIMEPULSE_GPIO_PORT);
	if (!ubloxeva8m_priv.gps_timepulse) {
		DBG_PRINTK("%s: Binding to gpio failed\n", __func__);
		return UBLOXEVA8M_BINDING_FAILED;
	}
	if (gpio_pin_configure(ubloxeva8m_priv.gps_timepulse, GPS_TIMEPULSE_GPIO_PIN, GPIO_DIR_IN)) {
		DBG_PRINTK("%s: Couldn't configure gpio\n", __func__);
		return UBLOXEVA8M_GPIO_ACCESS_FAILED;
	}

	return UBLOXEVA8M_SUCCESS;
}

int ubloxeva8m_power_on() {
	if (!ubloxeva8m_priv.gps_enable) {
		DBG_PRINTK("%s: Module not initialized\n", __func__);
		return UBLOXEVA8M_NOT_INITIALIZED;
	}
	if (gpio_pin_write(ubloxeva8m_priv.gps_enable, GPS_EN_GPIO_PIN, 1)) {
		DBG_PRINTK("%s: Couldn't write to gpio\n", __func__);
		return UBLOXEVA8M_GPIO_ACCESS_FAILED;
	}
	return UBLOXEVA8M_SUCCESS;
}

int ubloxeva8m_power_off() {
	if (!ubloxeva8m_priv.gps_enable) {
		DBG_PRINTK("%s: Module not initialized\n", __func__);
		return UBLOXEVA8M_NOT_INITIALIZED;
	}
	if (gpio_pin_write(ubloxeva8m_priv.gps_enable, GPS_EN_GPIO_PIN, 0)) {
		DBG_PRINTK("%s: Couldn't write to gpio\n", __func__);
		return UBLOXEVA8M_GPIO_ACCESS_FAILED;
	}
	return UBLOXEVA8M_SUCCESS;
}


int ubloxeva8m_start() {
	int status = ubloxeva8m_power_on();
	if (status != UBLOXEVA8M_SUCCESS) {
		return status;
	}
	/* Wait for the device to be ready */
	if (!ubloxeva8m_is_alive()) {
		DBG_PRINTK("%s: Module is not responding over i2c\n", __func__);
		return UBLOXEVA8M_NOT_ANSWERING;
	}

	/* Flush the stream */
	flush_stream();

	/* Start thread */
	/* TODO Remove flag, start thread when needed instead */
	ubloxeva8m_priv.is_thread_running = true;

	/* Configure protocol */
	status = configure_protocol();
	if (status != UBLOXEVA8M_SUCCESS) {
		return status;
	}

	/* Configuration message rates */
	status = configure_msg_rates(UBLOXEVA8M_CLASS_NAV, UBLOXEVA8M_MSG_NAV_PVT, 1);
	if (status != UBLOXEVA8M_SUCCESS) {
		return status;
	}

	return UBLOXEVA8M_SUCCESS;
}

void ubloxeva8m_set_callback(ubloxeva8m_msg_callback handler) {
	msg_handler = handler;
}

int ubloxeva8m_set_dynamic_model(ubloxeva8m_dynamic_models dyn_model) {
	ubloxeva8m_cfg_nav5_t msg;
	int status;

	msg.mask = UBLOXEVA8M_CFG_NAV5_MASK_DYN_MASK;
	msg.dynModel = dyn_model;

	status = send_msg(UBLOXEVA8M_CLASS_CFG, UBLOXEVA8M_MSG_CFG_NAV5, (uint8_t*)&msg, sizeof(msg));
	if (status) {
		return status;
	}

	/* Wait for Acknowledgment */
	if (!wait_for_ack()) {
		DBG_PRINTK("%s: Module returned NACK\n", __func__);
		return UBLOXEVA8M_NACK;
	}

	return UBLOXEVA8M_SUCCESS;
}

#ifdef DEBUG_MSG
static void print_msg(char* txt, ubloxeva8m_ubx_msg* msg) {
	char buf[256];
	snprintf(buf, 256, "%s Class: 0x%X Msg: 0x%X Len: %d Checksum: 0x%X Payload: 0x", txt, msg->class_id, msg->message_id, msg->length, msg->checksum);
	for(int i = 0; i < msg->length; i++) {
		snprintf(buf, 256, "%s%02X", buf, msg->payload[i]);
	}
	DBG_PRINTK("%s\n", buf);
}
#endif

/* Thread definition for the UBlox EVA 8M module */
K_THREAD_DEFINE(ubloxeva8m_thread_id, UBLOXEVA8M_STACKSIZE, ubloxeva8m_thread, NULL, NULL, NULL, UBLOXEVA8M_PRIORITY, 0, K_NO_WAIT);
```

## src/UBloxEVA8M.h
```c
/** 
 * @file UBloxEVA8M.h
 * @brief Module description
 *
 * Detailed module description
 *
 * @author Léonard Bise
 * @date   Jul 9, 2018
 */
#ifndef SRC_UBLOXEVA8M_H_
#define SRC_UBLOXEVA8M_H_

#include <zephyr.h>
#include "UBloxEVA8M_protocol.h"

#define UBLOXEVA8M_SUCCESS 0
#define UBLOXEVA8M_BINDING_FAILED -1
#define UBLOXEVA8M_CONFIGURATION_FAILED -2
#define UBLOXEVA8M_GPIO_ACCESS_FAILED -3
#define UBLOXEVA8M_NOT_INITIALIZED -4
#define UBLOXEVA8M_I2C_ACCESS_FAILED -5
#define UBLOXEVA8M_NOT_ANSWERING -6
#define UBLOXEVA8M_NULL_POINTER -7
#define UBLOXEVA8M_NACK -8
#define UBLOXEVA8M_BUSY -9

/**
 * Size of a message payload
 */
#define UBLOXEVA8M_MSG_PAYLOAD_BUFFER_SIZE 128

/**
 * Structure used to store a decoded message
 */
typedef struct __attribute__((packed,aligned(1))) {
	uint8_t class_id;
	uint8_t message_id;
	uint16_t length;
	uint8_t payload[UBLOXEVA8M_MSG_PAYLOAD_BUFFER_SIZE];
	uint16_t checksum;
	uint16_t stored_length;
} ubloxeva8m_ubx_msg;

/**
 * The dynamic models that can be configured
 */
typedef enum {
	UBLOXEVA8M_DYNMODEL_PORTABLE,
	UBLOXEVA8M_DYNMODEL_STATIONARY = 2,
	UBLOXEVA8M_DYNMODEL_PEDESTRIAN,
	UBLOXEVA8M_DYNMODEL_AUTOMOTIVE,
	UBLOXEVA8M_DYNMODEL_AT_SEA,
	UBLOXEVA8M_DYNMODEL_AIRBORNE_1G,
	UBLOXEVA8M_DYNMODEL_AIRBORNE_2G,
	UBLOXEVA8M_DYNMODEL_AIRBORNE_4G,
	UBLOXEVA8M_DYNMODEL_WRIST
} ubloxeva8m_dynamic_models;

/**
 * Type used for the callbacks
 * @param msg Message received
 */
typedef void (*ubloxeva8m_msg_callback)(ubloxeva8m_ubx_msg* msg);

/**
 * Initialze the UBlox EVA 8M module
 * @param device_name I2C device name
 * @return
 */
int ubloxeva8m_init(const char *device_name);

/**
 * Powers on the UBlox EVA 8M device
 * @return
 */
int ubloxeva8m_power_on();

/**
 * Powers off the UBlox EVA 8M device
 * @return
 */
int ubloxeva8m_power_off();

/**
 * Starts the module
 * @return
 */
int ubloxeva8m_start();

/**
 * Returns if the module is answering on the i2c bus
 * @return
 */
bool ubloxeva8m_is_alive();

/**
 * Sets a callback function on message received
 */
void ubloxeva8m_set_callback(ubloxeva8m_msg_callback handler);

/**
 * Sets the dynamic model to be used by the module
 * @param dyn_model
 * @return
 */
int ubloxeva8m_set_dynamic_model(ubloxeva8m_dynamic_models dyn_model);

#endif /* SRC_UBLOXEVA8M_H_ */
```

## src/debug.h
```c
/** 
 * @file debug.h
 * @brief Module description
 *
 * Detailed module description
 *
 * @author Léonard Bise
 * @date   Jun 29, 2018
 */
#ifndef SRC_DEBUG_H_
#define SRC_DEBUG_H_

#define DEBUG_RN2483_LORA 1
#define DEBUG_LSM303AGR 1
#define DEBUG_UBLOXEVA8M 1

#define DBG_PRINTK(fmt, ...) \
            do { if (DEBUG) printk(fmt, ## __VA_ARGS__); } while (0)

#endif /* SRC_DEBUG_H_ */
```
